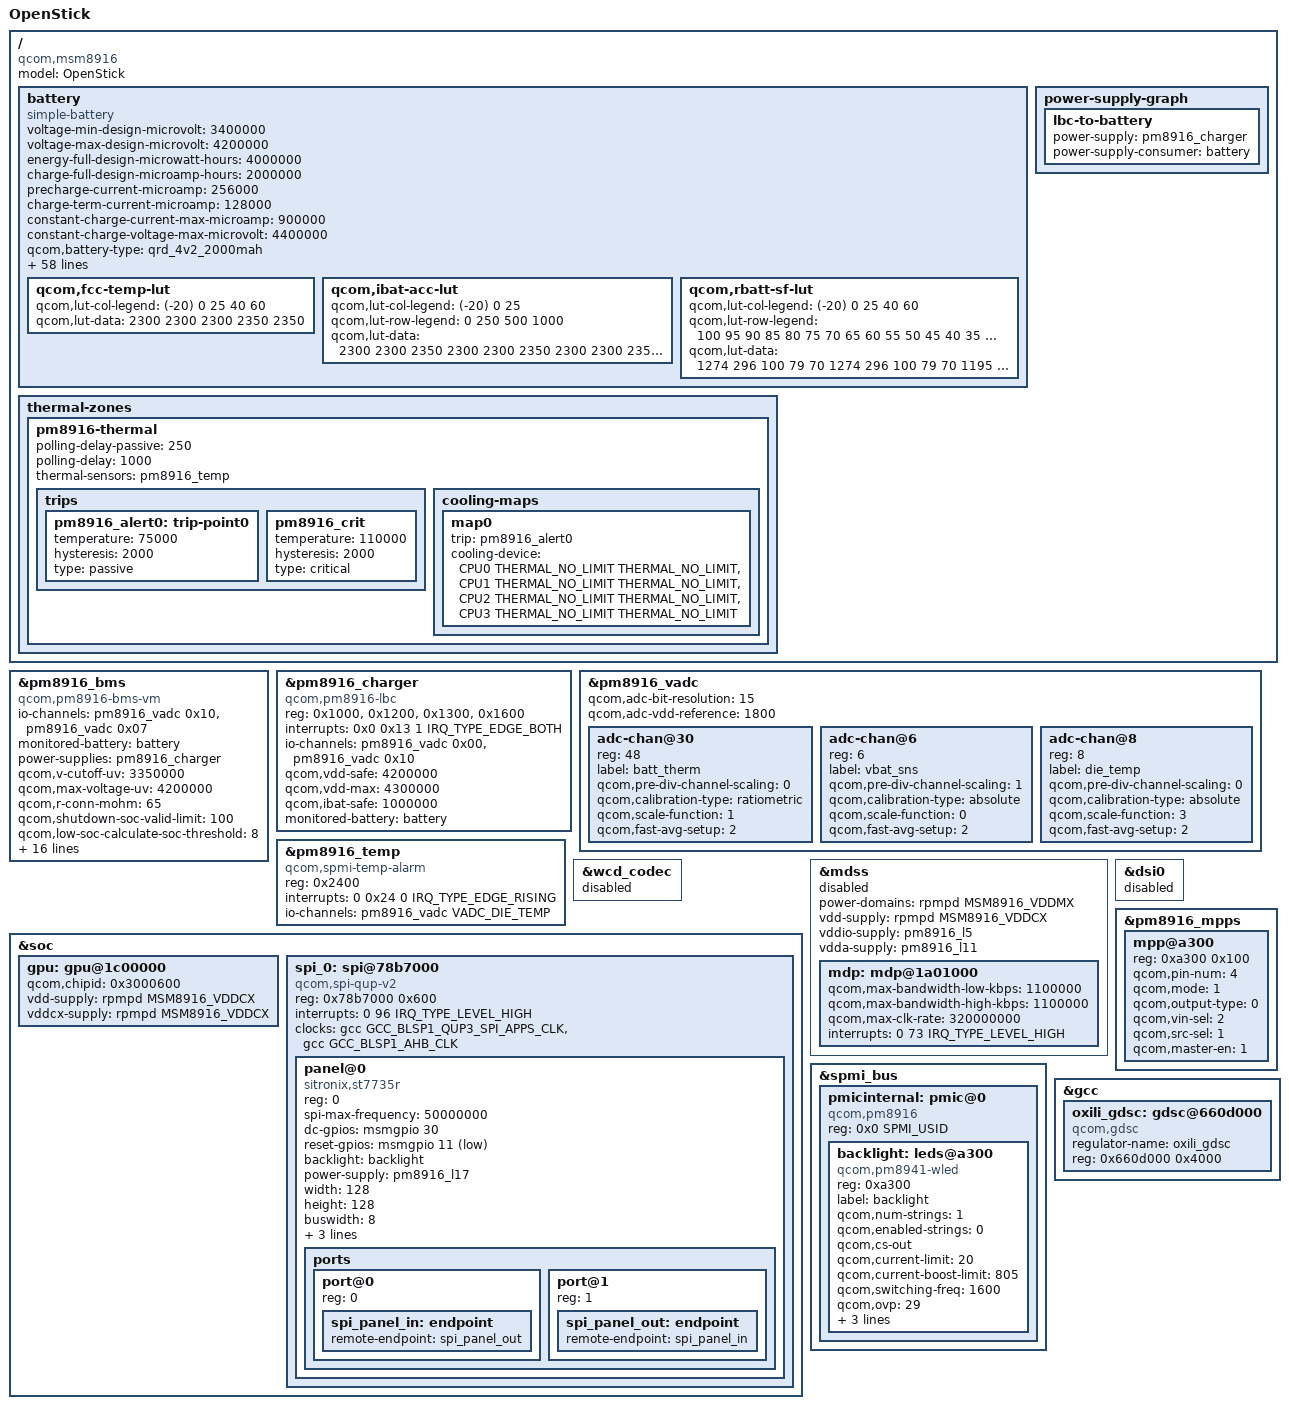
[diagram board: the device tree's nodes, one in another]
// SPDX-License-Identifier: GPL-2.0-only
/*
 * Copyright (C) 2024 TheNotOnly <darren.ramen@gmail.com>
 *
 */

/dts-v1/;
#include <dt-bindings/gpio/gpio.h>
#include "msm8916-handsome-openstick-common.dtsi"

/ {
	model = "OpenStick";
	compatible = "qcom,msm8916", "openstick,lte", "qcom,msm8916-cdp";

	battery: battery {
		compatible = "simple-battery";
		voltage-min-design-microvolt = <3400000>;
		voltage-max-design-microvolt = <4200000>;
		energy-full-design-microwatt-hours = <4000000>;
		charge-full-design-microamp-hours = <2000000>;
		precharge-current-microamp = <256000>;
		charge-term-current-microamp = <128000>;
		constant-charge-current-max-microamp = <900000>;
		constant-charge-voltage-max-microvolt = <4400000>;

		/* Added from old device tree data */
		qcom,battery-type = "qrd_4v2_2000mah";
		qcom,batt-id-kohm = <0>;
		qcom,chg-term-ua = <123976>;
		qcom,default-rbatt-mohm = <140>;
		qcom,fcc-mah = <2300>;
		qcom,max-voltage-uv = <4200000>;
		qcom,rbatt-capacitive-mohm = <60>;
		qcom,v-cutoff-uv = <3350000>;

		ocv-capacity-celsius = <(-20) 0 25 40 60>;
		ocv-capacity-table-0 = <4150000 100>, <4024000 95>, <3989000 90>, <3954000 85>, <3919000 80>,
						   <3862000 75>, <3834000 70>, <3808000 65>, <3786000 60>, <3769000 55>,
						   <3755000 50>, <3742000 45>, <3731000 40>, <3715000 35>, <3699000 30>,
						   <3683000 25>, <3667000 20>, <3639000 16>, <3612000 13>, <3595000 11>,
						   <3587000 10>, <3577000 9>, <3566000 8>, <3552000 7>, <3534000 6>,
						   <3512000 5>, <3484000 4>, <3447000 3>, <3394000 2>, <3318000 1>,
						   <3302000 0>;
		ocv-capacity-table-1 = <4150000 100>, <4029000 95>, <4002000 90>, <3977000 85>, <3950000 80>,
						   <3925000 75>, <3901000 70>, <3862000 65>, <3850000 60>, <3838000 55>,
						   <3829000 50>, <3816000 45>, <3803000 40>, <3795000 35>, <3787000 30>,
						   <3779000 25>, <3771000 20>, <3756000 16>, <3741000 13>, <3731000 11>,
						   <3727000 10>, <3717000 9>, <3706000 8>, <3688000 7>, <3660000 6>,
						   <3618000 5>, <3564000 4>, <3494000 3>, <3402000 2>, <3282000 1>,
						   <3278000 0>;
		ocv-capacity-table-2 = <4150000 100>, <4029000 95>, <4002000 90>, <3977000 85>, <3950000 80>,
						   <3925000 75>, <3901000 70>, <3862000 65>, <3850000 60>, <3838000 55>,
						   <3829000 50>, <3816000 45>, <3803000 40>, <3795000 35>, <3787000 30>,
						   <3779000 25>, <3771000 20>, <3756000 16>, <3741000 13>, <3731000 11>,
						   <3727000 10>, <3717000 9>, <3706000 8>, <3688000 7>, <3660000 6>,
						   <3618000 5>, <3564000 4>, <3494000 3>, <3402000 2>, <3282000 1>,
						   <3278000 0>;
		ocv-capacity-table-3 = <4150000 100>, <4029000 95>, <4002000 90>, <3977000 85>, <3950000 80>,
						   <3925000 75>, <3901000 70>, <3862000 65>, <3850000 60>, <3838000 55>,
						   <3829000 50>, <3816000 45>, <3803000 40>, <3795000 35>, <3787000 30>,
						   <3779000 25>, <3771000 20>, <3756000 16>, <3741000 13>, <3731000 11>,
						   <3727000 10>, <3717000 9>, <3706000 8>, <3688000 7>, <3660000 6>,
						   <3618000 5>, <3564000 4>, <3494000 3>, <3402000 2>, <3282000 1>,
						   <3278000 0>;
		ocv-capacity-table-4 = <4149000 100>, <4029000 95>, <4002000 90>, <3977000 85>, <3950000 80>,
						   <3925000 75>, <3901000 70>, <3862000 65>, <3850000 60>, <3838000 55>,
						   <3829000 50>, <3816000 45>, <3803000 40>, <3795000 35>, <3787000 30>,
						   <3779000 25>, <3771000 20>, <3756000 16>, <3741000 13>, <3731000 11>,
						   <3727000 10>, <3717000 9>, <3706000 8>, <3688000 7>, <3660000 6>,
						   <3618000 5>, <3564000 4>, <3494000 3>, <3402000 2>, <3282000 1>,
						   <3278000 0>;


		qcom,fcc-temp-lut {												//TO-DO
			qcom,lut-col-legend = <(-20) 0 25 40 60>;
			qcom,lut-data = <2300 2300 2300 2350 2350>;
		};

		qcom,ibat-acc-lut {												//TO-DO
			qcom,lut-col-legend = <(-20) 0 25>;
			qcom,lut-row-legend = <0 250 500 1000>;
			qcom,lut-data = <
				2300 2300 2350
				2300 2300 2350
				2300 2300 2350
				2300 2300 2350
			>;
		};

		qcom,rbatt-sf-lut {												//TO-DO
			qcom,lut-col-legend = <(-20) 0 25 40 60>;
			qcom,lut-row-legend = <100 95 90 85 80 75 70 65 60 55 50 45 40 35 30 25 20 16 13 11 10 9 8 7 6 5 4 3 2 1>;
			qcom,lut-data = <
				1274 296 100 79 70
				1274 296 100 79 70
				1195 321 105 81 71
				1134 313 109 84 73
				1117 317 116 87 75
				1108 316 123 90 77
				1102 312 132 96 80
				1131 311 137 104 85
				1172 310 114 103 89
				1215 306 105 81 73
				1257 320 104 81 71
				1304 348 106 83 74
				1352 384 106 85 76
				1406 422 112 88 78
				1471 460 117 88 77
				1550 531 120 84 72
				1645 600 124 86 73
				1829 660 128 87 73
				2091 678 127 86 73
				2333 690 130 87 74
				2621 738 134 89 75
				3022 764 140 93 77
				3564 820 148 94 79
				4303 831 149 96 79
				5399 892 157 98 78
				7100 956 160 97 77
				9604 1065 169 99 79
				14424 1228 192 105 82
				19407 1734 232 116 88
			>;
		};
	};

    power-supply-graph {
        lbc-to-battery {
            power-supply = <&pm8916_charger>;
            power-supply-consumer = <&battery>;
        };
    };

	/* Define thermal zones */
	thermal-zones {
		pm8916-thermal {
			polling-delay-passive = <250>;
			polling-delay = <1000>;

			thermal-sensors = <&pm8916_temp>;

			trips {
				pm8916_alert0: trip-point0 {
					temperature = <75000>;
					hysteresis = <2000>;
					type = "passive";
				};

				pm8916_crit: pm8916_crit {
					temperature = <110000>;
					hysteresis = <2000>;
					type = "critical";
				};
			};

			cooling-maps {
				map0 {
					trip = <&pm8916_alert0>;
					cooling-device = <&CPU0 THERMAL_NO_LIMIT THERMAL_NO_LIMIT>,
					<&CPU1 THERMAL_NO_LIMIT THERMAL_NO_LIMIT>,
					<&CPU2 THERMAL_NO_LIMIT THERMAL_NO_LIMIT>,
					<&CPU3 THERMAL_NO_LIMIT THERMAL_NO_LIMIT>;
				};
			};
		};
	};
};

&pm8916_bms {
	compatible = "qcom,pm8916-bms-vm";
	status = "okay";
	io-channels = <&pm8916_vadc 0x10>, /* LR_MUX1_BATT_THERM */
				<&pm8916_vadc 0x07>; /* VSYS */
	io-channel-names = "batt_therm", "vbat_sns";

	monitored-battery = <&battery>;
    power-supplies = <&pm8916_charger>;

	qcom,v-cutoff-uv = <3350000>;
	qcom,max-voltage-uv = <4200000>;
	qcom,r-conn-mohm = <65>;
	qcom,shutdown-soc-valid-limit = <100>;
	qcom,low-soc-calculate-soc-threshold = <8>;
	qcom,low-voltage-calculate-soc-ms = <5000>;
	qcom,low-soc-calculate-soc-ms = <5000>;
	qcom,calculate-soc-ms = <20000>;
	qcom,volatge-soc-timeout-ms = <60000>;
	qcom,low-voltage-threshold = <3450000>;
	qcom,s3-ocv-tolerence-uv = <1200>;
	qcom,s2-fifo-length = <5>;
	qcom,low-soc-fifo-length = <2>;
	qcom,bms-vadc = <&pm8916_vadc>;
//	qcom,bms-adc_tm = <&pm8916_adc_tm>;
//	qcom,pmic-revid = <&pm8916_revid>;
	qcom,force-s3-on-suspend;
	qcom,force-s2-in-charging;
	qcom,report-charger-eoc;
	qcom,resume-soc = <95>;
	qcom,use-reported-soc;
	qcom,force-bms-active-on-charger;
	qcom,ignore-shutdown-soc;
};

&pm8916_charger {
	compatible = "qcom,pm8916-lbc";
	reg = <0x1000>, <0x1200>, <0x1300>, <0x1600>;
	interrupts = <0x0 0x13 1 IRQ_TYPE_EDGE_BOTH>;
	io-channels = <&pm8916_vadc 0x00>, /* USBIN */
			    <&pm8916_vadc 0x10>; /* BAT_THERM */

	io-channel-names = "usb_in", "bat_therm";

	qcom,vdd-safe = <4200000>;  // 4200mV in microvolts
    qcom,vdd-max = <4300000>;   // 4300mV in microvolts
	qcom,ibat-safe = <1000000>; // 1000mA in microamps

	monitored-battery = <&battery>;

	status = "okay";
};

&pm8916_vadc {
	#address-cells = <1>;
	#size-cells = <0>;
	#io-channel-cells = <1>;

	/* Add any other missing properties */
	qcom,adc-bit-resolution = <15>;
	qcom,adc-vdd-reference = <1800>;

	/* Add missing channels */
	adc-chan@30 {
		reg = <48>;
		label = "batt_therm";
		qcom,pre-div-channel-scaling = <0>;
		qcom,calibration-type = "ratiometric";
		qcom,scale-function = <1>;
		qcom,fast-avg-setup = <2>;
	};

	adc-chan@6 {
		reg = <6>;
		label = "vbat_sns";
		qcom,pre-div-channel-scaling = <1>;
		qcom,calibration-type = "absolute";
		qcom,scale-function = <0>;
		qcom,fast-avg-setup = <2>;
	};

	adc-chan@8 {
		reg = <8>;
		label = "die_temp";
		qcom,pre-div-channel-scaling = <0>;
		qcom,calibration-type = "absolute";
		qcom,scale-function = <3>;
		qcom,fast-avg-setup = <2>;
	};
};

&pm8916_temp {
	compatible = "qcom,spmi-temp-alarm";
	reg = <0x2400>;
	interrupts = <0 0x24 0 IRQ_TYPE_EDGE_RISING>;
	io-channels = <&pm8916_vadc VADC_DIE_TEMP>;
	io-channel-names = "thermal";
	#thermal-sensor-cells = <0>;
};

&wcd_codec {
	status = "disabled";
};

&soc {
    gpu: gpu@1c00000 {
        qcom,chipid = <0x3000600>;
        vdd-supply = <&rpmpd MSM8916_VDDCX>;
        vddcx-supply = <&rpmpd MSM8916_VDDCX>;
    };

    spi_0: spi@78b7000 {
        compatible = "qcom,spi-qup-v2";
        reg = <0x78b7000 0x600>;
        interrupts = <0 96 IRQ_TYPE_LEVEL_HIGH>;
        clocks = <&gcc GCC_BLSP1_QUP3_SPI_APPS_CLK>,
                 <&gcc GCC_BLSP1_AHB_CLK>;
        clock-names = "core", "iface";
        #address-cells = <1>;
        #size-cells = <0>;
        status = "okay";
        
        panel@0 {
            compatible = "sitronix,st7735r";
            reg = <0>;
            spi-max-frequency = <50000000>;
            dc-gpios = <&msmgpio 30 GPIO_ACTIVE_HIGH>;
            reset-gpios = <&msmgpio 11 GPIO_ACTIVE_LOW>;
            backlight = <&backlight>;
            power-supply = <&pm8916_l17>;
            width = <128>;
            height = <128>;
            buswidth = <8>;
            rotate = <0>;
            fps = <30>;
            rgb;

            ports {
                #address-cells = <1>;
                #size-cells = <0>;

                port@0 {
                    reg = <0>;

                    spi_panel_in: endpoint {
                        remote-endpoint = <&spi_panel_out>;
                    };
                };

                port@1 {
                    reg = <1>;

                    spi_panel_out: endpoint {
                        remote-endpoint = <&spi_panel_in>;
                    };
                };
            };
        };
    };
};

&mdss {
    status = "disabled";
    power-domains = <&rpmpd MSM8916_VDDMX>;
    vdd-supply = <&rpmpd MSM8916_VDDCX>;
    vddio-supply = <&pm8916_l5>;
    vdda-supply = <&pm8916_l11>;

    #address-cells = <1>;
    #size-cells = <1>;

    mdp: mdp@1a01000 {
        status = "okay";
        qcom,max-bandwidth-low-kbps = <1100000>;
        qcom,max-bandwidth-high-kbps = <1100000>;
        qcom,max-clk-rate = <320000000>;
        interrupts = <0 73 IRQ_TYPE_LEVEL_HIGH>;
    };
};

&dsi0 {
    status = "disabled";
};

&pm8916_mpps {
    #address-cells = <1>;
    #size-cells = <1>;
    mpp@a300 {
        reg = <0xa300 0x100>;
        qcom,pin-num = <4>;
        qcom,mode = <1>;        /* Digital output */
        qcom,output-type = <0>; /* CMOS */
        qcom,vin-sel = <2>;     /* S4 1.8V */
        qcom,src-sel = <1>;     /* Special Function 1 = Manual mode */
        qcom,master-en = <1>;   /* Enable MPP */
        status = "okay";
    };
};

&spmi_bus {
    #address-cells = <2>;
    #size-cells = <0>;
    
    pmicinternal: pmic@0 {
        compatible = "qcom,pm8916", "qcom,spmi-pmic";
        #address-cells = <1>;
        #size-cells = <0>;
        reg = <0x0 SPMI_USID>;

        backlight: leds@a300 {
            compatible = "qcom,pm8941-wled";
            reg = <0xa300>;
            label = "backlight";
            qcom,num-strings = <1>;
            qcom,enabled-strings = <0>;
            qcom,cs-out;
            qcom,current-limit = <20>;
            qcom,current-boost-limit = <805>;
            qcom,switching-freq = <1600>;
            qcom,ovp = <29>;
            
            interrupt-names = "ovp";

            linux,name = "lcd-backlight";
            linux,default-trigger = "bkl-trigger";
            
            status = "okay";
        };
    };
};

&gcc {
    #address-cells = <1>;
    #size-cells = <1>;
    oxili_gdsc: gdsc@660d000 {
        compatible = "qcom,gdsc";
        regulator-name = "oxili_gdsc";
        reg = <0x660d000 0x4000>;
        status = "okay";
    };
};

&backlight {
    enable-gpios = <&msmgpio 98 GPIO_ACTIVE_HIGH>;
};
